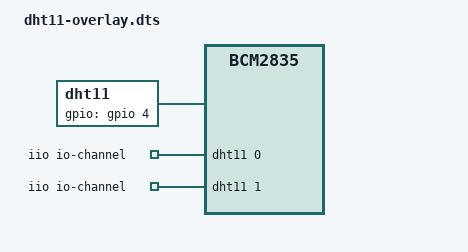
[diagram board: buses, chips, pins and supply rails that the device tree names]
/*
 * Overlay for the DHT11/21/22 humidity/temperature sensor modules.
 */
/dts-v1/;
/plugin/;

#include <dt-bindings/gpio/gpio.h>

/ {
	compatible = "brcm,bcm2835";

	fragment@0 {
		target-path = "/";
		__overlay__ {
			dht11: dht11@4 {
				compatible = "dht11";
				gpios = <&gpio 4 (GPIO_ACTIVE_HIGH | GPIO_PULL_DISABLE)>;
				status = "okay";
				#io-channel-cells = <1>;
			};

			iio: iio-hwmon@4 {
				compatible = "iio-hwmon";
				status = "okay";
				io-channels = <&dht11 0>, <&dht11 1>;
			};
		};
	};

	__overrides__ {
		gpiopin = <&dht11>,"gpios:4",
			<&dht11>,"reg:0",
			<&iio>,"reg:0";
	};
};
